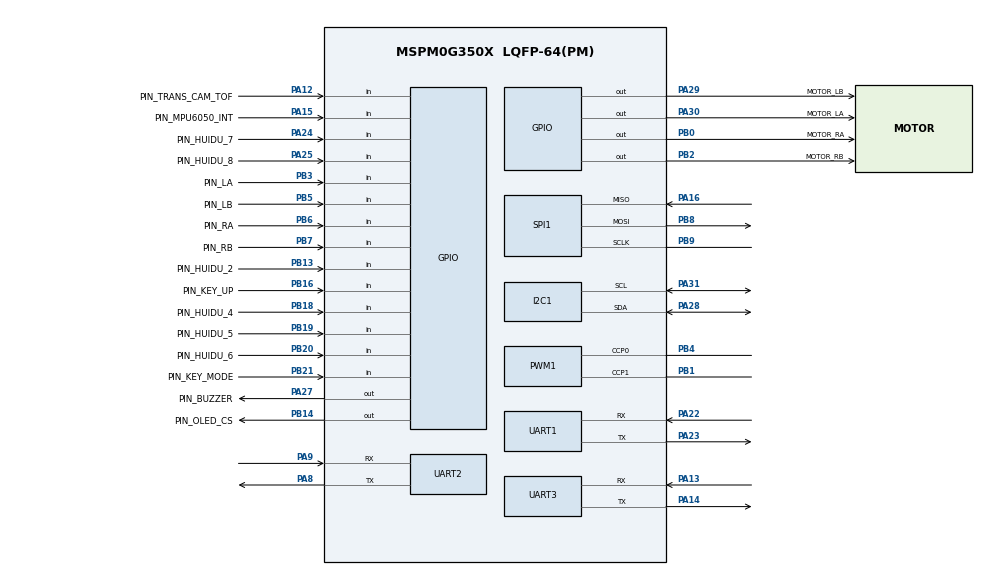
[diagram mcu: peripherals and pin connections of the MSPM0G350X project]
/**
 * @cliArgs --device "MSPM0G350X" --part "Default" --package "LQFP-64(PM)" --product "mspm0_sdk@2.05.01.00"
 * @versions {"tool":"1.24.0+4110"}
 */

/**
 * Import the modules used in this configuration.
 */
const GPIO   = scripting.addModule("/ti/driverlib/GPIO", {}, false);
const GPIO1  = GPIO.addInstance();
const GPIO2  = GPIO.addInstance();
const GPIO3  = GPIO.addInstance();
const GPIO4  = GPIO.addInstance();
const GPIO5  = GPIO.addInstance();
const GPIO6  = GPIO.addInstance();
const GPIO7  = GPIO.addInstance();
const GPIO8  = GPIO.addInstance();
const GPIO9  = GPIO.addInstance();
const I2C    = scripting.addModule("/ti/driverlib/I2C", {}, false);
const I2C1   = I2C.addInstance();
const I2C2   = I2C.addInstance();
const PWM    = scripting.addModule("/ti/driverlib/PWM", {}, false);
const PWM1   = PWM.addInstance();
const SPI    = scripting.addModule("/ti/driverlib/SPI", {}, false);
const SPI1   = SPI.addInstance();
const SYSCTL = scripting.addModule("/ti/driverlib/SYSCTL");
const TIMER  = scripting.addModule("/ti/driverlib/TIMER", {}, false);
const TIMER1 = TIMER.addInstance();
const UART   = scripting.addModule("/ti/driverlib/UART", {}, false);
const UART1  = UART.addInstance();
const UART2  = UART.addInstance();
const UART3  = UART.addInstance();
const UART4  = UART.addInstance();

/**
 * Write custom configuration values to the imported modules.
 */
const divider7       = system.clockTree["PLL_PDIV"];
divider7.divideValue = 2;

const divider9       = system.clockTree["UDIV"];
divider9.divideValue = 2;

const multiplier2         = system.clockTree["PLL_QDIV"];
multiplier2.multiplyValue = 5;

const mux8       = system.clockTree["HSCLKMUX"];
mux8.inputSelect = "HSCLKMUX_SYSPLL2X";

GPIO1.$name                               = "Encoder";
GPIO1.associatedPins.create(4);
GPIO1.associatedPins[0].direction         = "INPUT";
GPIO1.associatedPins[0].assignedPin       = "5";
GPIO1.associatedPins[0].interruptPriority = "2";
GPIO1.associatedPins[0].$name             = "PIN_LB";
GPIO1.associatedPins[0].pin.$assign       = "PB5";
GPIO1.associatedPins[1].direction         = "INPUT";
GPIO1.associatedPins[1].internalResistor  = "PULL_DOWN";
GPIO1.associatedPins[1].assignedPin       = "3";
GPIO1.associatedPins[1].$name             = "PIN_LA";
GPIO1.associatedPins[1].interruptEn       = true;
GPIO1.associatedPins[1].polarity          = "RISE";
GPIO1.associatedPins[1].interruptPriority = "2";
GPIO1.associatedPins[1].pin.$assign       = "PB3";
GPIO1.associatedPins[2].$name             = "PIN_RA";
GPIO1.associatedPins[2].direction         = "INPUT";
GPIO1.associatedPins[2].interruptEn       = true;
GPIO1.associatedPins[2].polarity          = "RISE";
GPIO1.associatedPins[2].assignedPin       = "6";
GPIO1.associatedPins[2].interruptPriority = "2";
GPIO1.associatedPins[2].pin.$assign       = "PB6";
GPIO1.associatedPins[3].$name             = "PIN_RB";
GPIO1.associatedPins[3].direction         = "INPUT";
GPIO1.associatedPins[3].assignedPin       = "7";
GPIO1.associatedPins[3].pin.$assign       = "PB7";

const Board = scripting.addModule("/ti/driverlib/Board", {}, false);

GPIO2.$name                         = "MOTOR";
GPIO2.associatedPins.create(4);
GPIO2.associatedPins[0].$name       = "MOTOR_LA";
GPIO2.associatedPins[0].assignedPin = "30";
GPIO2.associatedPins[0].pin.$assign = "PA30";
GPIO2.associatedPins[1].$name       = "MOTOR_LB";
GPIO2.associatedPins[1].assignedPin = "29";
GPIO2.associatedPins[1].pin.$assign = "PA29";
GPIO2.associatedPins[2].$name       = "MOTOR_RA";
GPIO2.associatedPins[2].assignedPin = "0";
GPIO2.associatedPins[2].pin.$assign = "PB0";
GPIO2.associatedPins[3].$name       = "MOTOR_RB";
GPIO2.associatedPins[3].assignedPin = "2";
GPIO2.associatedPins[3].pin.$assign = "PB2";

GPIO3.$name                          = "GPIO_OLED";
GPIO3.associatedPins.create(4);
GPIO3.associatedPins[0].$name        = "PIN_OLED_RES";
GPIO3.associatedPins[0].assignedPort = "PORTB";
GPIO3.associatedPins[0].initialValue = "SET";
GPIO3.associatedPins[0].assignedPin  = "10";
GPIO3.associatedPins[1].$name        = "PIN_OLED_DC";
GPIO3.associatedPins[1].assignedPort = "PORTB";
GPIO3.associatedPins[1].assignedPin  = "11";
GPIO3.associatedPins[2].initialValue = "SET";
GPIO3.associatedPins[2].$name        = "PIN_OLED_CS";
GPIO3.associatedPins[2].assignedPort = "PORTB";
GPIO3.associatedPins[2].assignedPin  = "14";
GPIO3.associatedPins[2].pin.$assign  = "PB14";
GPIO3.associatedPins[3].$name        = "PIN_OLED_BLK";
GPIO3.associatedPins[3].initialValue = "SET";
GPIO3.associatedPins[3].assignedPort = "PORTB";
GPIO3.associatedPins[3].assignedPin  = "26";

GPIO4.$name                              = "GPIO_TRANS";
GPIO4.port                               = "PORTA";
GPIO4.associatedPins[0].$name            = "PIN_TRANS_CAM_TOF";
GPIO4.associatedPins[0].direction        = "INPUT";
GPIO4.associatedPins[0].internalResistor = "PULL_UP";
GPIO4.associatedPins[0].pin.$assign      = "PA12";

GPIO5.$name                          = "GPIO_MPU6050";
GPIO5.associatedPins[0].$name        = "PIN_MPU6050_INT";
GPIO5.associatedPins[0].assignedPort = "PORTA";
GPIO5.associatedPins[0].direction    = "INPUT";
GPIO5.associatedPins[0].interruptEn  = true;
GPIO5.associatedPins[0].polarity     = "RISE";
GPIO5.associatedPins[0].pin.$assign  = "PA15";

GPIO6.$name                                 = "GPIO_KEY";
GPIO6.associatedPins.create(3);
GPIO6.associatedPins[0].direction           = "INPUT";
GPIO6.associatedPins[0].assignedPort        = "PORTB";
GPIO6.associatedPins[0].assignedPortSegment = "Upper";
GPIO6.associatedPins[0].assignedPin         = "21";
GPIO6.associatedPins[0].$name               = "PIN_KEY_MODE";
GPIO6.associatedPins[0].internalResistor    = "PULL_UP";
GPIO6.associatedPins[0].pin.$assign         = "PB21";
GPIO6.associatedPins[1].direction           = "INPUT";
GPIO6.associatedPins[1].assignedPortSegment = "Upper";
GPIO6.associatedPins[1].$name               = "PIN_KEY_UP";
GPIO6.associatedPins[1].internalResistor    = "PULL_UP";
GPIO6.associatedPins[1].assignedPort        = "PORTB";
GPIO6.associatedPins[1].assignedPin         = "16";
GPIO6.associatedPins[1].pin.$assign         = "PB16";
GPIO6.associatedPins[2].direction           = "INPUT";
GPIO6.associatedPins[2].assignedPort        = "PORTA";
GPIO6.associatedPins[2].assignedPortSegment = "Upper";
GPIO6.associatedPins[2].assignedPin         = "17";
GPIO6.associatedPins[2].$name               = "PIN_KEY_DOWN";
GPIO6.associatedPins[2].internalResistor    = "PULL_UP";

GPIO7.$name                          = "GPIO_BUZZER";
GPIO7.port                           = "PORTA";
GPIO7.portSegment                    = "Upper";
GPIO7.associatedPins[0].$name        = "PIN_BUZZER";
GPIO7.associatedPins[0].initialValue = "SET";
GPIO7.associatedPins[0].pin.$assign  = "PA27";

GPIO8.$name                              = "GPIO_HUIDU";
GPIO8.associatedPins.create(8);
GPIO8.associatedPins[0].direction        = "INPUT";
GPIO8.associatedPins[0].internalResistor = "PULL_UP";
GPIO8.associatedPins[0].assignedPort     = "PORTB";
GPIO8.associatedPins[0].assignedPin      = "12";
GPIO8.associatedPins[0].$name            = "PIN_HUIDU_1";
GPIO8.associatedPins[1].$name            = "PIN_HUIDU_2";
GPIO8.associatedPins[1].direction        = "INPUT";
GPIO8.associatedPins[1].assignedPort     = "PORTB";
GPIO8.associatedPins[1].assignedPin      = "13";
GPIO8.associatedPins[1].internalResistor = "PULL_UP";
GPIO8.associatedPins[1].pin.$assign      = "PB13";
GPIO8.associatedPins[2].$name            = "PIN_HUIDU_3";
GPIO8.associatedPins[2].direction        = "INPUT";
GPIO8.associatedPins[2].internalResistor = "PULL_UP";
GPIO8.associatedPins[2].assignedPin      = "15";
GPIO8.associatedPins[3].internalResistor = "PULL_UP";
GPIO8.associatedPins[3].$name            = "PIN_HUIDU_4";
GPIO8.associatedPins[3].direction        = "INPUT";
GPIO8.associatedPins[3].assignedPort     = "PORTB";
GPIO8.associatedPins[3].assignedPin      = "18";
GPIO8.associatedPins[3].pin.$assign      = "PB18";
GPIO8.associatedPins[4].$name            = "PIN_HUIDU_5";
GPIO8.associatedPins[4].direction        = "INPUT";
GPIO8.associatedPins[4].internalResistor = "PULL_UP";
GPIO8.associatedPins[4].assignedPort     = "PORTB";
GPIO8.associatedPins[4].assignedPin      = "19";
GPIO8.associatedPins[4].pin.$assign      = "PB19";
GPIO8.associatedPins[5].$name            = "PIN_HUIDU_6";
GPIO8.associatedPins[5].direction        = "INPUT";
GPIO8.associatedPins[5].internalResistor = "PULL_UP";
GPIO8.associatedPins[5].assignedPort     = "PORTB";
GPIO8.associatedPins[5].assignedPin      = "20";
GPIO8.associatedPins[5].pin.$assign      = "PB20";
GPIO8.associatedPins[6].$name            = "PIN_HUIDU_7";
GPIO8.associatedPins[6].direction        = "INPUT";
GPIO8.associatedPins[6].internalResistor = "PULL_UP";
GPIO8.associatedPins[6].assignedPort     = "PORTA";
GPIO8.associatedPins[6].assignedPin      = "24";
GPIO8.associatedPins[6].pin.$assign      = "PA24";
GPIO8.associatedPins[7].$name            = "PIN_HUIDU_8";
GPIO8.associatedPins[7].direction        = "INPUT";
GPIO8.associatedPins[7].internalResistor = "PULL_UP";
GPIO8.associatedPins[7].assignedPort     = "PORTA";
GPIO8.associatedPins[7].assignedPin      = "25";
GPIO8.associatedPins[7].pin.$assign      = "PA25";

GPIO9.$name                   = "GPIO_LED";
GPIO9.associatedPins[0].$name = "PIN_LED_BOARD";

I2C1.basicEnableController             = true;
I2C1.$name                             = "I2C_MPU6050";
I2C1.basicControllerBusSpeed           = 400000;
I2C1.peripheral.sdaPin.$assign         = "PA28";
I2C1.peripheral.sclPin.$assign         = "PA31";
I2C1.sdaPinConfig.$name                = "ti_driverlib_gpio_GPIOPinGeneric0";
I2C1.sdaPinConfig.hideOutputInversion  = scripting.forceWrite(false);
I2C1.sdaPinConfig.onlyInternalResistor = scripting.forceWrite(false);
I2C1.sdaPinConfig.passedPeripheralType = scripting.forceWrite("Digital");
I2C1.sclPinConfig.$name                = "ti_driverlib_gpio_GPIOPinGeneric1";
I2C1.sclPinConfig.hideOutputInversion  = scripting.forceWrite(false);
I2C1.sclPinConfig.onlyInternalResistor = scripting.forceWrite(false);
I2C1.sclPinConfig.passedPeripheralType = scripting.forceWrite("Digital");

I2C2.$name                             = "I2C_0";
I2C2.sdaPinConfig.hideOutputInversion  = scripting.forceWrite(false);
I2C2.sdaPinConfig.onlyInternalResistor = scripting.forceWrite(false);
I2C2.sdaPinConfig.passedPeripheralType = scripting.forceWrite("Digital");
I2C2.sdaPinConfig.$name                = "ti_driverlib_gpio_GPIOPinGeneric6";
I2C2.sclPinConfig.hideOutputInversion  = scripting.forceWrite(false);
I2C2.sclPinConfig.onlyInternalResistor = scripting.forceWrite(false);
I2C2.sclPinConfig.passedPeripheralType = scripting.forceWrite("Digital");
I2C2.sclPinConfig.$name                = "ti_driverlib_gpio_GPIOPinGeneric7";

PWM1.$name                              = "Motor";
PWM1.timerCount                         = 8000;
PWM1.peripheral.$assign                 = "TIMA1";
PWM1.peripheral.ccp0Pin.$assign         = "PB4";
PWM1.peripheral.ccp1Pin.$assign         = "PB1";
PWM1.PWM_CHANNEL_0.$name                = "ti_driverlib_pwm_PWMTimerCC0";
PWM1.PWM_CHANNEL_1.$name                = "ti_driverlib_pwm_PWMTimerCC1";
PWM1.ccp0PinConfig.direction            = scripting.forceWrite("OUTPUT");
PWM1.ccp0PinConfig.hideOutputInversion  = scripting.forceWrite(false);
PWM1.ccp0PinConfig.onlyInternalResistor = scripting.forceWrite(false);
PWM1.ccp0PinConfig.passedPeripheralType = scripting.forceWrite("Digital");
PWM1.ccp0PinConfig.$name                = "ti_driverlib_gpio_GPIOPinGeneric2";
PWM1.ccp1PinConfig.direction            = scripting.forceWrite("OUTPUT");
PWM1.ccp1PinConfig.hideOutputInversion  = scripting.forceWrite(false);
PWM1.ccp1PinConfig.onlyInternalResistor = scripting.forceWrite(false);
PWM1.ccp1PinConfig.passedPeripheralType = scripting.forceWrite("Digital");
PWM1.ccp1PinConfig.$name                = "ti_driverlib_gpio_GPIOPinGeneric3";

SPI1.$name                              = "SPI_OLED";
SPI1.targetBitRate                      = 10000000;
SPI1.peripheral.$assign                 = "SPI1";
SPI1.peripheral.sclkPin.$assign         = "PB9";
SPI1.peripheral.mosiPin.$assign         = "PB8";
SPI1.peripheral.misoPin.$assign         = "PA16";
SPI1.sclkPinConfig.direction            = scripting.forceWrite("OUTPUT");
SPI1.sclkPinConfig.onlyInternalResistor = scripting.forceWrite(false);
SPI1.sclkPinConfig.passedPeripheralType = scripting.forceWrite("Digital");
SPI1.sclkPinConfig.$name                = "ti_driverlib_gpio_GPIOPinGeneric14";
SPI1.mosiPinConfig.direction            = scripting.forceWrite("OUTPUT");
SPI1.mosiPinConfig.hideOutputInversion  = scripting.forceWrite(false);
SPI1.mosiPinConfig.onlyInternalResistor = scripting.forceWrite(false);
SPI1.mosiPinConfig.passedPeripheralType = scripting.forceWrite("Digital");
SPI1.mosiPinConfig.$name                = "ti_driverlib_gpio_GPIOPinGeneric15";
SPI1.misoPinConfig.onlyInternalResistor = scripting.forceWrite(false);
SPI1.misoPinConfig.passedPeripheralType = scripting.forceWrite("Digital");
SPI1.misoPinConfig.$name                = "ti_driverlib_gpio_GPIOPinGeneric16";
SPI1.cs0PinConfig.direction             = scripting.forceWrite("OUTPUT");
SPI1.cs0PinConfig.hideOutputInversion   = scripting.forceWrite(false);
SPI1.cs0PinConfig.onlyInternalResistor  = scripting.forceWrite(false);
SPI1.cs0PinConfig.passedPeripheralType  = scripting.forceWrite("Digital");
SPI1.cs0PinConfig.$name                 = "ti_driverlib_gpio_GPIOPinGeneric17";

SYSCTL.forceDefaultClkConfig = true;
SYSCTL.clockTreeEn           = true;
scripting.suppress("For best practices when the CPUCLK is running at 32MHz and above, clear the flash status bit using DL_FlashCTL_executeClearStatus\\(\\) before executing any flash operation\\. Otherwise there may be false positives\\.", SYSCTL);

TIMER1.$name            = "TIMER_0";
TIMER1.timerClkDiv      = 4;
TIMER1.timerMode        = "PERIODIC";
TIMER1.interrupts       = ["ZERO"];
TIMER1.timerClkPrescale = 200;
TIMER1.timerPeriod      = "10.00ms";
TIMER1.timerStartTimer  = true;

UART1.enabledInterrupts                = ["RX"];
UART1.targetBaudRate                   = 115200;
UART1.$name                            = "UART_BNO08";
UART1.enabledDMARXTriggers             = "DL_UART_DMA_INTERRUPT_RX";
UART1.peripheral.$assign               = "UART2";
UART1.peripheral.rxPin.$assign         = "PA22";
UART1.peripheral.txPin.$assign         = "PA23";
UART1.txPinConfig.direction            = scripting.forceWrite("OUTPUT");
UART1.txPinConfig.hideOutputInversion  = scripting.forceWrite(false);
UART1.txPinConfig.onlyInternalResistor = scripting.forceWrite(false);
UART1.txPinConfig.passedPeripheralType = scripting.forceWrite("Digital");
UART1.txPinConfig.$name                = "ti_driverlib_gpio_GPIOPinGeneric4";
UART1.rxPinConfig.hideOutputInversion  = scripting.forceWrite(false);
UART1.rxPinConfig.onlyInternalResistor = scripting.forceWrite(false);
UART1.rxPinConfig.passedPeripheralType = scripting.forceWrite("Digital");
UART1.rxPinConfig.$name                = "ti_driverlib_gpio_GPIOPinGeneric5";
UART1.DMA_CHANNEL_RX.$name             = "DMA_BNO08X";

UART2.enabledInterrupts                = ["RX"];
UART2.$name                            = "UART_CAM";
UART2.targetBaudRate                   = 115200;
UART2.peripheral.rxPin.$assign         = "PA9";
UART2.peripheral.txPin.$assign         = "PA8";
UART2.txPinConfig.direction            = scripting.forceWrite("OUTPUT");
UART2.txPinConfig.hideOutputInversion  = scripting.forceWrite(false);
UART2.txPinConfig.onlyInternalResistor = scripting.forceWrite(false);
UART2.txPinConfig.passedPeripheralType = scripting.forceWrite("Digital");
UART2.txPinConfig.$name                = "ti_driverlib_gpio_GPIOPinGeneric8";
UART2.rxPinConfig.hideOutputInversion  = scripting.forceWrite(false);
UART2.rxPinConfig.onlyInternalResistor = scripting.forceWrite(false);
UART2.rxPinConfig.passedPeripheralType = scripting.forceWrite("Digital");
UART2.rxPinConfig.$name                = "ti_driverlib_gpio_GPIOPinGeneric9";

UART3.$name                            = "UART_bj1";
UART3.targetBaudRate                   = 115200;
UART3.enabledInterrupts                = ["RX"];
UART3.peripheral.rxPin.$assign         = "PA13";
UART3.peripheral.txPin.$assign         = "PA14";
UART3.txPinConfig.direction            = scripting.forceWrite("OUTPUT");
UART3.txPinConfig.hideOutputInversion  = scripting.forceWrite(false);
UART3.txPinConfig.onlyInternalResistor = scripting.forceWrite(false);
UART3.txPinConfig.passedPeripheralType = scripting.forceWrite("Digital");
UART3.txPinConfig.$name                = "ti_driverlib_gpio_GPIOPinGeneric10";
UART3.rxPinConfig.hideOutputInversion  = scripting.forceWrite(false);
UART3.rxPinConfig.onlyInternalResistor = scripting.forceWrite(false);
UART3.rxPinConfig.passedPeripheralType = scripting.forceWrite("Digital");
UART3.rxPinConfig.$name                = "ti_driverlib_gpio_GPIOPinGeneric11";

UART4.$name                            = "UART_bj2";
UART4.targetBaudRate                   = 115200;
UART4.enabledInterrupts                = ["RX"];
UART4.txPinConfig.direction            = scripting.forceWrite("OUTPUT");
UART4.txPinConfig.hideOutputInversion  = scripting.forceWrite(false);
UART4.txPinConfig.onlyInternalResistor = scripting.forceWrite(false);
UART4.txPinConfig.passedPeripheralType = scripting.forceWrite("Digital");
UART4.txPinConfig.$name                = "ti_driverlib_gpio_GPIOPinGeneric12";
UART4.rxPinConfig.hideOutputInversion  = scripting.forceWrite(false);
UART4.rxPinConfig.onlyInternalResistor = scripting.forceWrite(false);
UART4.rxPinConfig.passedPeripheralType = scripting.forceWrite("Digital");
UART4.rxPinConfig.$name                = "ti_driverlib_gpio_GPIOPinGeneric13";

/**
 * Pinmux solution for unlocked pins/peripherals. This ensures that minor changes to the automatic solver in a future
 * version of the tool will not impact the pinmux you originally saw.  These lines can be completely deleted in order to
 * re-solve from scratch.
 */
Board.peripheral.$suggestSolution                = "DEBUGSS";
Board.peripheral.swclkPin.$suggestSolution       = "PA20";
Board.peripheral.swdioPin.$suggestSolution       = "PA19";
GPIO3.associatedPins[0].pin.$suggestSolution     = "PB10";
GPIO3.associatedPins[1].pin.$suggestSolution     = "PB11";
GPIO3.associatedPins[3].pin.$suggestSolution     = "PB26";
GPIO6.associatedPins[2].pin.$suggestSolution     = "PA17";
GPIO8.associatedPins[0].pin.$suggestSolution     = "PB12";
GPIO8.associatedPins[2].pin.$suggestSolution     = "PB15";
GPIO9.associatedPins[0].pin.$suggestSolution     = "PA18";
I2C1.peripheral.$suggestSolution                 = "I2C0";
I2C2.peripheral.$suggestSolution                 = "I2C1";
I2C2.peripheral.sdaPin.$suggestSolution          = "PA10";
I2C2.peripheral.sclPin.$suggestSolution          = "PA11";
SPI1.peripheral.cs0Pin.$suggestSolution          = "PA2";
TIMER1.peripheral.$suggestSolution               = "TIMA0";
UART1.DMA_CHANNEL_RX.peripheral.$suggestSolution = "DMA_CH0";
UART2.peripheral.$suggestSolution                = "UART1";
UART3.peripheral.$suggestSolution                = "UART3";
UART4.peripheral.$suggestSolution                = "UART0";
UART4.peripheral.rxPin.$suggestSolution          = "PA1";
UART4.peripheral.txPin.$suggestSolution          = "PA0";
